# RT584ZCM33 register map
Series: ARMv8-M Mainline; File version: 1.0
CPU: CM33 r0p0, little endian, MPU, no FPU, VTOR, 3 interrupt priority bits
Registers are 32-bit, read-write, reset 0x0 unless marked. A register's access mark holds for its fields unless they carry their own. Offsets are from the block's base; [hi:lo] are bit positions; {n}, {i} and the like mark numbered series.

## QSPI0_Non-Secure — QSPI0 Non-Secure Register block
Base 0x40020000
Same registers: QSPI1_Non-Secure 0x40021000, QSPI0_Secure 0x50020000, QSPI1_Secure 0x50021000
0x00 QSPI_TXF_REG wo — Serial Transmit Data Register
0x04 QSPI_RXF_REG ro — Serial Receive Data Register
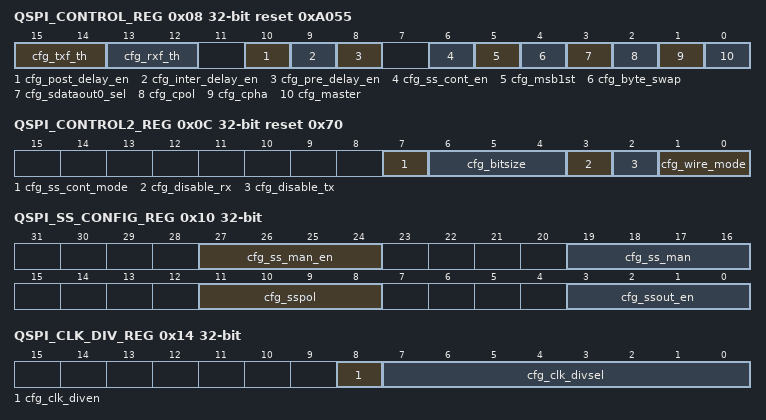
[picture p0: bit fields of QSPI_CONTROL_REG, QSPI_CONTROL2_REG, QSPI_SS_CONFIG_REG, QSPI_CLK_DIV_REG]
0x08 QSPI_CONTROL_REG reset 0xA055 — qspi control
  [15:14] cfg_txf_th — Sets the threshold level for TX FIFO operation, QSPI_FIFO_DEPTH=32 0: QSPI_FIFO_DEPTH/8 1: QSPI_FIFO_DEPTH/4 2: QSPI_FIFO_DEPTH/2 3: QSPI_FIFO_DEPTH/2+QSPI_FIFO_DEPTH/4
    0=B_14_to_15_ITEM0 (QSPI_FIFO_DEPTH/8); 1=B_14_to_15_ITEM1 (QSPI_FIFO_DEPTH/4); 2=B_14_to_15_ITEM2 (QSPI_FIFO_DEPTH/2); 3=B_14_to_15_ITEM3 (QSPI_FIFO_DEPTH/2+QSPI_FIFO_DEPTH/4)
  [13:12] cfg_rxf_th — Sets the threshold level for RX FIFO operation, QSPI_FIFO_DEPTH=32 0: QSPI_FIFO_DEPTH/8 1: QSPI_FIFO_DEPTH/4 2: QSPI_FIFO_DEPTH/2 3: QSPI_FIFO_DEPTH/2+QSPI_FIFO_DEPTH/4
    0=B_12_to_13_ITEM0 (QSPI_FIFO_DEPTH/8); 1=B_12_to_13_ITEM1 (QSPI_FIFO_DEPTH/4); 2=B_12_to_13_ITEM2 (QSPI_FIFO_DEPTH/2); 3=B_12_to_13_ITEM3 (QSPI_FIFO_DEPTH/2+QSPI_FIFO_DEPTH/4)
  [10] cfg_post_delay_en — Post delay for Master operation. After data, add delay between ssOut inactive and last SCLK edge. 0: disable delay 1: enable delay
    0=B_10_ITEM0 (disable delay); 1=B_10_ITEM1 (enable delay)
  [9] cfg_inter_delay_en — Inter-transfer delay for Master operation. 0: disable delay 1: enable delay
    0=B_9_ITEM0 (disable delay); 1=B_9_ITEM1 (enable delay)
  [8] cfg_pre_delay_en — Pre delay for Master operation. Before data, add delay between ssOut active and first SCLK edge. 0: disable delay 1: enable delay
    0=B_8_ITEM0 (disable delay); 1=B_8_ITEM1 (enable delay)
  [6] cfg_ss_cont_en — Continuous Transfer bit. This is relevant for Master operation only.
    0=B_6 (Continuous Transfer bit. This is relevant for Master operation only.)
  [5] cfg_msb1st — Bit order of data tranfer. 0: LSB first 1: MSB first
    0=B_5_ITEM0 (LSB first); 1=B_5_ITEM1 (MSB first)
  [4] cfg_byte_swap — Byte swap when bitsize = 16/32 bit for TX/RX FIFO. Only valid when cfg_msb1st=1.
    0=B_4 (Byte swap when bitsize = 16/32 bit for TX/RX FIFO. Only valid when cfg_msb1st=1.)
  [3] cfg_sdataout0_sel — For normal SPI mode (cfg_wire_mode==2'b00), set 0 for master and set 1 for slave. 0: SDATA[0]=sdata_out[0], sdata_in[0]=SDATA[1]. 1: SDATA[1]=sdata_out[0], sdata_in[0]=SDATA[0].
    0=B_3_ITEM0 (SDATA[0]=sdata_out[0], sdata_in[0]=SDATA[1].); 1=B_3_ITEM1 (SDATA[1]=sdata_out[0], sdata_in[0]=SDATA[0].)
  [2] cfg_cpol — SPI clock polarity select 0: SPI clock rests low 1: SPI clock rests high
    0=B_2_ITEM0 (SPI clock rests low); 1=B_2_ITEM1 (SPI clock rests high)
  [1] cfg_cpha — SPI clock phase select 0: first bit(s) of sdataOut occur as SS is asserted. 1: sdataOut occurs on first SPI clock edge after SS.
    0=B_1_ITEM0 (first bit(s) of sdataOut occur as SS is asserted.); 1=B_1_ITEM1 (sdataOut occurs on first SPI clock edge after SS.)
  [0] cfg_master — SPI role select 0: slave mode 1: master mode
    0=B_0_ITEM0 (slave mode); 1=B_0_ITEM1 (master mode)
0x0C QSPI_CONTROL2_REG reset 0x70 — qspi control2
  [7] cfg_ss_cont_mode — Continuous Transfer Extend Bit. This is relevant for Master operation only. Further, this bit has no effect if the contXfer bit is 0. This register bit is synchronized to the SCLK domain for use there. Note that this setting also affects the timing of the master output enable signal, sdataOutEnMN. 0: to have ssOut[x] become inactive when the TX FIFO is empty. 1: to have ssOut[x] remain active even when the TX FIFO is empty.
    0=B_7_ITEM0 (to have ssOut[x] become inactive when the TX FIFO is empty.); 1=B_7_ITEM1 (to have ssOut[x] remain active even when the TX FIFO is empty.)
  [6:4] cfg_bitsize — Number of bits in each transfer and FIFO. Only 8/16/32 bits are supported for RT583 1: 8 bit serial mode, 3: 16 bit serial mode, 7: 32 bit serial mode, others: invalid NOTE that the 32-bit FIFO is consumed for each data no matter the bitsize. For DMA mode, 8/16/32 bit mode consume 8/16/32 bits memory.
    0=B_4_to_6 (Number of bits in each transfer and FIFO. Only 8/16/32 bits are supported for RT583 1: 8 bit serial mode, 3: 16 bit serial mode, 7: 32 bit serial mode, others: invalid NOTE that the 32-bit FIFO is consumed for each data no matter the bitsize. For DMA mode, 8/16/32 bit mode consume 8/16/32 bits memory.)
  [3] cfg_disable_rx — Set to 1 to inhibit the SPI serializers from writing to the Receive FIFO. In Quad or Dual mode, it's needed to set 1 for TX and 0 for RX
    0=B_3 (Set to 1 to inhibit the SPI serializers from writing to the Receive FIFO. In Quad or Dual mode, it's needed to set 1 for TX and 0 for RX)
  [2] cfg_disable_tx — Set to 1 to inhibit the SPI serializers from reading the Transmit FIFO. I'ts only for Slave mode, In Master mode, it should be set to 0.
    0=B_2 (Set to 1 to inhibit the SPI serializers from reading the Transmit FIFO. I'ts only for Slave mode, In Master mode, it should be set to 0.)
  [1:0] cfg_wire_mode — Spi wire Modes: 0: Normal SPI 1: invalid 2: Dual SPI 3: Quad SPI
    0=B_0_to_1_ITEM0 (Normal SPI); 1=B_0_to_1_ITEM1 (invalid); 2=B_0_to_1_ITEM2 (Dual SPI); 3=B_0_to_1_ITEM3 (Quad SPI)
0x10 QSPI_SS_CONFIG_REG — qspi ss config
  [27:24] cfg_ss_man_en — Enable manual control of 4 spi_ss pins. The priority of cfg_ss_man_en is higher than cfg_ssout_en
    0=B_24_to_27 (Enable manual control of 4 spi_ss pins. The priority of cfg_ss_man_en is higher than cfg_ssout_en)
  [19:16] cfg_ss_man — Manual control of 4 spi_ss pins, Only valid when corresponding cfg_ss_man_en = 1
    0=B_16_to_19 (Manual control of 4 spi_ss pins, Only valid when corresponding cfg_ss_man_en = 1)
  [11:8] cfg_sspol — ss polarity 0: cfg_ssout[3/2/1/0] (Master) or ssIn (Slave) is an active low signal 1: cfg_ssout[3/2/1/0] (Master) or ssIn (Slave) is an active high signal
    0=B_8_to_11 (ss polarity 0: cfg_ssout[3/2/1/0] (Master) or ssIn (Slave) is an active low signal 1: cfg_ssout[3/2/1/0] (Master) or ssIn (Slave) is an active high signal)
  [3:0] cfg_ssout_en — ss select enable 0: Do not select slave 3/2/1/0 for TX/RX. 1: Select Slave 0 for TX/RX.
    0=B_0_to_3 (ss select enable 0: Do not select slave 3/2/1/0 for TX/RX. 1: Select Slave 0 for TX/RX.)
0x14 QSPI_CLK_DIV_REG — qspi clk div
  [8] cfg_clk_diven — Master clock divider enable 0: Master clock = per_clk (default is 32 MHz) 1: Master clock = divided clock.
    0=B_8_ITEM0 (Master clock = per_clk (default is 32 MHz)); 1=B_8_ITEM1 (Master clock = divided clock.)
  [7:0] cfg_clk_divsel — Master clock divider select. Master clock is from per_clk, which can be 32M/16M/RCO1M. Below values are based on 32M. 0: 32/2 = 16 MHz, 1: 32/4 = 8 MHz, 2: 32/6 = 5.333 MHz, 3: 32/8 = 4 MHz, 255: 32/512 = 62.5 KHz
    0=B_0_to_7 (Master clock divider select. Master clock is from per_clk, which can be 32M/16M/RCO1M. Below values are based on 32M. 0: 32/2 = 16 MHz, 1: 32/4 = 8 MHz, 2: 32/6 = 5.333 MHz, 3: 32/8 = 4 MHz, 255: 32/512 = 62.5 KHz)
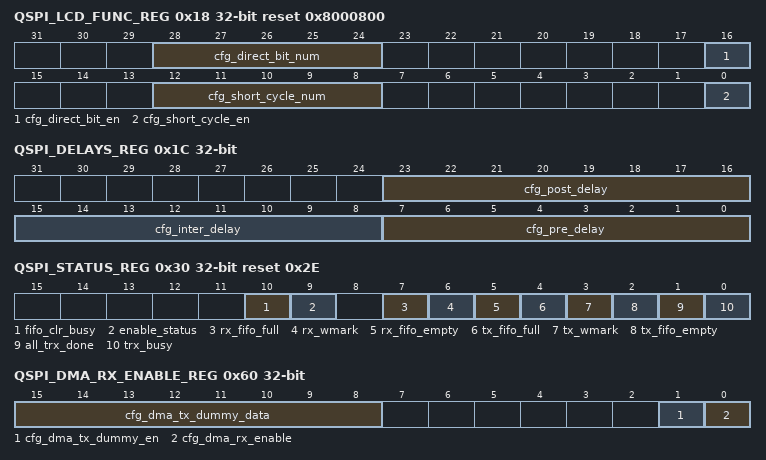
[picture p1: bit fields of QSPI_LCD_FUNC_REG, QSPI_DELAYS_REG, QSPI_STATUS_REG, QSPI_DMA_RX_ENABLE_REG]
0x18 QSPI_LCD_FUNC_REG reset 0x8000800 — qspi lcd func
  [28:24] cfg_direct_bit_num — Select the bit position from MEM/FIFO to MOSI[1]
    0=B_24_to_28 (Select the bit position from MEM/FIFO to MOSI[1])
  [16] cfg_direct_bit_en — Enable of direct bit. Used in 32bit normal mode. Master only The selected bit goes to MOSI[1]
    0=B_16 (Enable of direct bit. Used in 32bit normal mode. Master only The selected bit goes to MOSI[1])
  [12:8] cfg_short_cycle_num — Determine the data cycles. 0: 1 cycle 1: 2 cycles 2: 3 cycles 3: 4 cycles 4: 5 cycles 5: 6 cycles 6: 7 cycles 7: 8 cycles 8: 9 cycles 9: 10 cycles 10: 11 cycles 11: 12 cycles 12: 13 cycles 13: 14 cycles 14: 15 cycles 15: 16 cycles 16: 17 cycles 17: 18 cycles 18: 19 cycles 19: 20 cycles 20: 21 cycles 21: 22 cycles 22: 23 cycles 23: 24 cycles 24: 25 cycles 25: 26 cycles 26: 27 cycles 27: 28 cycles 28: 29 cycles 29: 30 cycles 30: 31 cycles 31: 32 cycles
    0=B_8_to_12_ITEM0 (1 cycle); {v}=B_8_to_12_ITEM{v} ({v+1} cycles) (v=1..31)
  [0] cfg_short_cycle_en — Enable of short cycle. Used for non 8/16/32 bits data. Master only
    0=B_0 (Enable of short cycle. Used for non 8/16/32 bits data. Master only)
0x1C QSPI_DELAYS_REG — qspi delays
  [23:16] cfg_post_delay — It's valid when cfg_post_delay_en = 1, this register sets the pre delay for the master serializer. The delay is (cfg_post_delay+1) SCLK cycles.
    0=B_16_to_23 (It's valid when cfg_post_delay_en = 1, this register sets the pre delay for the master serializer. The delay is (cfg_post_delay+1) SCLK cycles.)
  [15:8] cfg_inter_delay — It's valid when cfg_inter_delay_en = 1, this register sets the inter delay for the master serializer. The delay is (cfg_inter_delay+1) SCLK cycles.
    0=B_8_to_15 (It's valid when cfg_inter_delay_en = 1, this register sets the inter delay for the master serializer. The delay is (cfg_inter_delay+1) SCLK cycles.)
  [7:0] cfg_pre_delay — It's valid when cfg_pre_delay_en = 1, this register sets the pre delay for the master serializer. The delay is (cfg_pre_delay+1) SCLK cycles.
    0=B_0_to_7 (It's valid when cfg_pre_delay_en = 1, this register sets the pre delay for the master serializer. The delay is (cfg_pre_delay+1) SCLK cycles.)
0x20 QSPI_INTR_EN_REG — qspi intr en
  [5:0] cfg_intr_en_legacy — Write 1 to enable individual interrupts (see Interrupt Mapping). A read will return a status of the enabled interrupts. [0] tx_fifo_empty [1] ! tx_wmark [2] rx_wmark [3] rx_fifo_full [4] ! xferIP [5] rx_fifo_not_empty
    0=B_0_to_5 (Write 1 to enable individual interrupts (see Interrupt Mapping). A read will return a status of the enabled interrupts. [0] tx_fifo_empty [1] ! tx_wmark [2] rx_wmark [3] rx_fifo_full [4] ! xferIP [5] rx_fifo_not_empty)
0x24 QSPI_INTR_STATUS_REG ro — qspi intr status
  [5:0] intr_status_legacy — Interrupt Status 0: no interrupt 1: interrupt source is active
    0=B_0_to_5 (Interrupt Status 0: no interrupt 1: interrupt source is active)
0x28 QSPI_INTR_CLR_REG wo — qspi intr clr
  [5:0] intr_clr_legacy — Clear Interrupt Writing a 1 clears the interrupt bit. Writing a 0 has no effect.
    0=B_0_to_5 (Clear Interrupt Writing a 1 clears the interrupt bit. Writing a 0 has no effect.)
0x2C QSPI_EN_REG — qspi en
  [0] cfg_enable wo — SPI enable. Read enable_status_ext to check the real status in design 0: Disable SPI TX and RX; reset RX and TX FIFOs on the transition from 1 to 0 of this bit. 1: Enable SPI TX and RX.
    0=B_0_ITEM0 (Disable SPI TX and RX; reset RX and TX FIFOs on the transition from 1 to 0 of this bit.); 1=B_0_ITEM1 (Enable SPI TX and RX.)
  [0] enable_status_ext ro — It's (enable_status | fifo_clr_busy). SW need to wait for it being 0 after set cfg_enable from 1 to 0
    0=B_0 (It's (enable_status | fifo_clr_busy). SW need to wait for it being 0 after set cfg_enable from 1 to 0)
0x30 QSPI_STATUS_REG ro reset 0x2E — qspi status
  [10] fifo_clr_busy — (Debug use only) FIFO clear busy flag when cfg_enable from 1 to 0
    0=B_10 ((Debug use only) FIFO clear busy flag when cfg_enable from 1 to 0)
  [9] enable_status — (Debug use only) The real enable sync to serializer after cfg_enable change. Only changeable when xferIP is 0.
    0=B_9 ((Debug use only) The real enable sync to serializer after cfg_enable change. Only changeable when xferIP is 0.)
  [7] rx_fifo_full — Receive FIFO full flag
    0=B_7 (Receive FIFO full flag)
  [6] rx_wmark — Receive FIFO watermark flag
    0=B_6 (Receive FIFO watermark flag)
  [5] rx_fifo_empty — Receive FIFO empty flag
    0=B_5 (Receive FIFO empty flag)
  [4] tx_fifo_full — Transmit FIFO full flag
    0=B_4 (Transmit FIFO full flag)
  [3] tx_wmark — Transmit FIFO watermark flag
    0=B_3 (Transmit FIFO watermark flag)
  [2] tx_fifo_empty — Transmit FIFO empty flag
    0=B_2 (Transmit FIFO empty flag)
  [1] all_trx_done — tx_fifo_empty & !trx_busy
    0=B_1 (tx_fifo_empty & !trx_busy)
  [0] trx_busy — Transfer is in progress (ssOut/ssIn is active)
    0=B_0 (Transfer is in progress (ssOut/ssIn is active))
0x34 QSPI_TX_FIFO_LVL_REG ro — qspi tx fifo lvl
  [5:0] tx_level — Read transmit FIFO current level (0-32).
    0=B_0_to_5 (Read transmit FIFO current level (0-32).)
0x38 QSPI_RX_FIFO_LVL_REG ro — qspi rx fifo lvl
  [5:0] rx_level — Read receive FIFO current level (0-32).
    0=B_0_to_5 (Read receive FIFO current level (0-32).)
0x40 QSPI_DMA_RX_BASE_REG — Base address of DMA Rx
0x44 QSPI_DMA_RX_LENGTH_REG — qspi dma rx length
  [15:0] cfg_dma_rx_length — Length of DMA Rx
0x48 QSPI_DMA_TX_BASE_REG — Base address of DMA Tx
0x4C QSPI_DMA_TX_LENGTH_REG — qspi dma tx length
  [15:0] cfg_dma_tx_length — Length of DMA Tx
0x50 QSPI_DMA_RX_REMAIN_REG ro — qspi dma rx remain
  [15:0] qpsi_dma_rx_remain_len — Remain length of DMA Rx
0x54 QSPI_DMA_TX_REMAIN_REG ro — qspi dma tx remain
  [15:0] qpsi_dma_tx_remain_len — Remain length of DMA Tx
0x58 QSPI_DMA_INTR_EN_REG — qspi dma intr en
  [1:0] cfg_intr_en_dma — Enable of DMA interrupt [0] dma_rx_done [1] dma_tx_done
    0=B_0_to_1 (Enable of DMA interrupt [0] dma_rx_done [1] dma_tx_done)
0x5C QSPI_DMA_INTR_STATUS_CLR_REG — qspi dma intr status clr
  [1:0] intr_clr_dma wo — Clear Interrupt Writing a 1 clears the interrupt bit. Writing a 0 has no effect.
    0=B_0_to_1 (Clear Interrupt Writing a 1 clears the interrupt bit. Writing a 0 has no effect.)
  [1:0] intr_status_dma ro — Interrupt Status 1 = interrupt source is active, 0 = no interrupt
    0=B_0_to_1 (Interrupt Status 1 = interrupt source is active, 0 = no interrupt)
0x60 QSPI_DMA_RX_ENABLE_REG — qspi dma rx enable
  [15:8] cfg_dma_tx_dummy_data — Dummy data for tx dummy contorl
    0=B_8_to_15 (Dummy data for tx dummy contorl)
  [1] cfg_dma_tx_dummy_en — Enable tx dummy control to trigger master to work for Rx case
    0=B_1 (Enable tx dummy control to trigger master to work for Rx case)
  [0] cfg_dma_rx_enable — Enable of DMA Rx
    0=B_0 (Enable of DMA Rx)
0x64 QSPI_DMA_TX_ENABLE_REG — qspi dma tx enable
  [0] cfg_dma_tx_enable — Enable of DMA Tx
    0=B_0 (Enable of DMA Tx)
